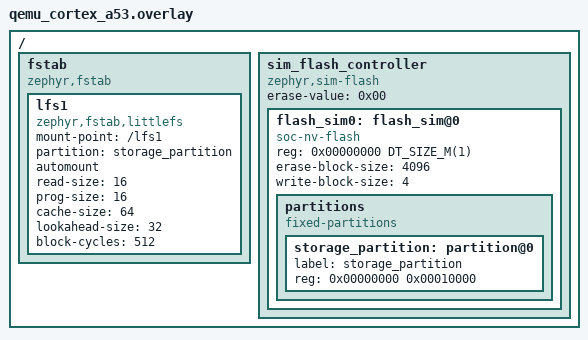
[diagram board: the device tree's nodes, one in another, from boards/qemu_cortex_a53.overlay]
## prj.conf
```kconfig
CONFIG_LOG=y
CONFIG_LOG_MODE_MINIMAL=y

# CONFIG_MODULES must be enabled to allow setting any options to "m" in the
# Kconfig files. For compatibility with Kconfiglib, the name must be kept
# as-is even if Zephyr has a completely different concept for "modules".

CONFIG_MODULES=y

# LLEXT is only required when loading the extension at runtime. Since in this
# basic example there's only one llext, leaving it in when building the
# extension as a built-in is redundant; in a real application, however, there
# could be other uses of the llext subsystem.

CONFIG_LLEXT=y
CONFIG_LLEXT_LOG_LEVEL_DBG=y
CONFIG_LLEXT_HEAP_SIZE=64
CONFIG_LLEXT_TYPE_ELF_RELOCATABLE=y # supported by all targets

# This test consumes large amounts of stack when loading the LLEXT.
# Increase the available size to avoid overflowing (see issue #74536).

CONFIG_MAIN_STACK_SIZE=2048

# NOTE
#
# This project file explicitly does NOT include the configuration for
# CONFIG_HELLO_WORLD_MODE, so a clean compile will include the function as
# built-in by default.
#
# To build it as an llext, please follow the instructions in the documentation
# of this sample; there are architecture-specific settings that must be set in
# addition to CONFIG_HELLO_WORLD_MODE=m. For example, most ARM targets need to
# either enable CONFIG_USERSPACE (if they support it) or disable MPU/MMU
# features for LLEXT to work correctly.

# Kconfig symbols for interactive shell
CONFIG_SHELL=y
CONFIG_LLEXT_SHELL=y
CONFIG_FILE_SYSTEM_SHELL=y
CONFIG_HEAP_MEM_POOL_SIZE=512

# Filesystem configuration
CONFIG_FILE_SYSTEM=y
CONFIG_FILE_SYSTEM_LITTLEFS=y
CONFIG_FS_LITTLEFS_FMP_DEV=y
CONFIG_FLASH_MAP=y
CONFIG_FLASH=y
```

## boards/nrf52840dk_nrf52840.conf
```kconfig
CONFIG_ARM_MPU=n

CONFIG_NORDIC_QSPI_NOR=y
CONFIG_NORDIC_QSPI_NOR_FLASH_LAYOUT_PAGE_SIZE=4096
```

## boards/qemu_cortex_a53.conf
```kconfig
CONFIG_FLASH_SIMULATOR_SEMIHOST=y
```

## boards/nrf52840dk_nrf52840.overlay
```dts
/delete-node/ &storage_partition;

/ {
	fstab {
		compatible = "zephyr,fstab";
		lfs1: lfs1 {
			compatible = "zephyr,fstab,littlefs";
			mount-point = "/lfs1";
			partition = <&storage_partition>;
			automount;
			read-size = <16>;
			prog-size = <16>;
			cache-size = <64>;
			lookahead-size = <32>;
			block-cycles = <512>;
		};
	};
};

&mx25r64 {
	partitions {
		compatible = "fixed-partitions";
		#address-cells = <1>;
		#size-cells = <1>;

		storage_partition: partition@0 {
			label = "storage_partition";
			reg = <0x00000000 0x00010000>;
		};
	};
};
```

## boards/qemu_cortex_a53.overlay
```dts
/*
 * Copyright (c) 2024 BayLibre SAS
 *
 * SPDX-License-Identifier: Apache-2.0
 */

#include <mem.h>

 / {
	fstab {
		compatible = "zephyr,fstab";
		lfs1: lfs1 {
			compatible = "zephyr,fstab,littlefs";
			mount-point = "/lfs1";
			partition = <&storage_partition>;
			automount;
			read-size = <16>;
			prog-size = <16>;
			cache-size = <64>;
			lookahead-size = <32>;
			block-cycles = <512>;
		};
	};

	sim_flash_controller: sim_flash_controller {
		compatible = "zephyr,sim-flash";

		#address-cells = <1>;
		#size-cells = <1>;
		erase-value = <0x00>;

		flash_sim0: flash_sim@0 {
			compatible = "soc-nv-flash";
			reg = <0x00000000 DT_SIZE_M(1)>;

			erase-block-size = <4096>;
			write-block-size = <4>;

			partitions {
				compatible = "fixed-partitions";
				#address-cells = <1>;
				#size-cells = <1>;

				storage_partition: partition@0 {
					label = "storage_partition";
					reg = <0x00000000 0x00010000>;
				};
			};
		};
	};
};
```

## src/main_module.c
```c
/*
 * Copyright (c) 2024 Arduino SA
 *
 * SPDX-License-Identifier: Apache-2.0
 */

#include <zephyr/kernel.h>

#define LOG_LEVEL CONFIG_LOG_DEFAULT_LEVEL
#include <zephyr/logging/log.h>
LOG_MODULE_REGISTER(app);


int main(void)
{

	while (true) {
		k_sleep(K_MSEC(100));
	}

	return 0;
}
```
